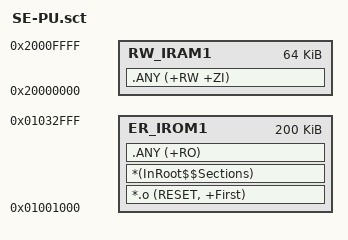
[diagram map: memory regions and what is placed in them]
; *************************************************************
; *** Scatter-Loading Description File generated by uVision ***
; *************************************************************

LR_IROM1 0x01001000 0x0032000  {    ; load region size_region
  ER_IROM1 0x01001000 0x0032000  {  ; load address = execution address
 ;*(.ARM.__at_0x01001100)
 *.o (RESET, +First)
   *(InRoot$$Sections)
   .ANY (+RO)
  }
  RW_IRAM1 0x20000000 0x00010000  {  ; RW data
   .ANY (+RW +ZI)
  }
}

